AUTOSAR XML (schema 4-0-3)
package /ComponentTypes
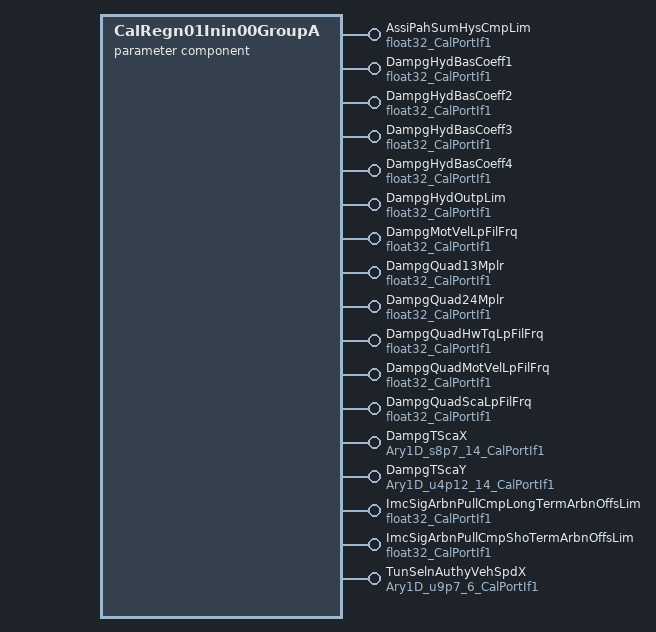
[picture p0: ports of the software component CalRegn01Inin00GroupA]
  parameter sw component type CalRegn01Inin00GroupA
    17 x provide port:
      AssiPahSumHysCmpLim: parameter-provide-com-spec{init-value=0.2, parameter=Val}, provided-interface=float32_CalPortIf1
      DampgHydBasCoeff1: parameter-provide-com-spec{init-value=0.0005, parameter=Val}, provided-interface=float32_CalPortIf1
      DampgHydBasCoeff2: parameter-provide-com-spec{init-value=2e-05, parameter=Val}, provided-interface=float32_CalPortIf1
      DampgHydBasCoeff3: parameter-provide-com-spec{init-value=0.006, parameter=Val}, provided-interface=float32_CalPortIf1
      DampgHydBasCoeff4: parameter-provide-com-spec{init-value=9e-06, parameter=Val}, provided-interface=float32_CalPortIf1
      DampgHydOutpLim: parameter-provide-com-spec{init-value=0, parameter=Val}, provided-interface=float32_CalPortIf1
      DampgMotVelLpFilFrq: parameter-provide-com-spec{init-value=15, parameter=Val}, provided-interface=float32_CalPortIf1
      DampgQuad13Mplr: parameter-provide-com-spec{init-value=1, parameter=Val}, provided-interface=float32_CalPortIf1
      DampgQuad24Mplr: parameter-provide-com-spec{init-value=1, parameter=Val}, provided-interface=float32_CalPortIf1
      DampgQuadHwTqLpFilFrq: parameter-provide-com-spec{init-value=15, parameter=Val}, provided-interface=float32_CalPortIf1
      DampgQuadMotVelLpFilFrq: parameter-provide-com-spec{init-value=15, parameter=Val}, provided-interface=float32_CalPortIf1
      DampgQuadScaLpFilFrq: parameter-provide-com-spec{init-value=15, parameter=Val}, provided-interface=float32_CalPortIf1
      DampgTScaX: parameter-provide-com-spec{init-value=[-5120, -4480, -3840, -2560, -1280, 0, 1280, 2560, 3840, 5120, 6400, 7680, 8960, 11520], parameter=Ary1D}, provided-interface=Ary1D_s8p7_14_CalPortIf1
      DampgTScaY: parameter-provide-com-spec{init-value=14 x 4096, parameter=Ary1D}, provided-interface=Ary1D_u4p12_14_CalPortIf1
      ImcSigArbnPullCmpLongTermArbnOffsLim: parameter-provide-com-spec{init-value=8, parameter=Val}, provided-interface=float32_CalPortIf1
      ImcSigArbnPullCmpShoTermArbnOffsLim: parameter-provide-com-spec{init-value=8, parameter=Val}, provided-interface=float32_CalPortIf1
      TunSelnAuthyVehSpdX: parameter-provide-com-spec{init-value=[0, 12800, 25600, 38400, 51200, 65408], parameter=Ary1D}, provided-interface=Ary1D_u9p7_6_CalPortIf1
